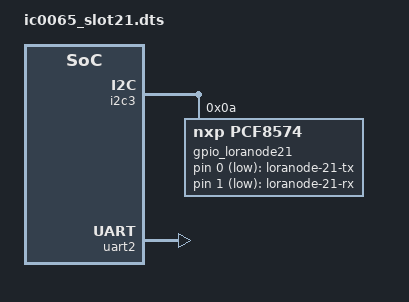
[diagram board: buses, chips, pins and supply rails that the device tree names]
/dts-v1/;


/plugin/;

/ {
	fragment@0 {
		target = <&i2c3>;
		__overlay__ {
			#address-cells = <1>;
			#size-cells = <0>;
			gpio_loranode21: pca9501@10 {
				compatible = "nxp,pcf8574";
				gpio-controller;
				#gpio-cells = <2>;
				reg = <10>;
				lines-initial-states = <0x10>;
				gpio-line-names = "SLOT21_LORANODE_LED1",
				"SLOT21_LORANODE_LED2",
				"SLOT21_LORANODE_CTS",
				"SLOT21_LORANODE_RTS",
				"SLOT21_LORANODE_RESET",
				"SLOT21_LORANODE_BOOT",
				"",
				"";
			};
		};
	};

	fragment@3 {
		
		target = <&uart2>;
		__overlay__ {
			status = "okay";
		};

	};

	fragment@4 {
		target-path = "/";
		__overlay__ {
			loraleds {
				compatible = "gpio-leds";
				lora-led@0 {
					label = "loranode-21-tx";
					gpios = <&gpio_loranode21 0 1>;
					default-state = "off";
					linux,default-trigger = "none";
				};
				lora-led@1 {
					label = "loranode-21-rx";
					gpios = <&gpio_loranode21 1 1>;
					default-state = "off";
					linux,default-trigger = "none";
				};
			};
		};
	};
};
